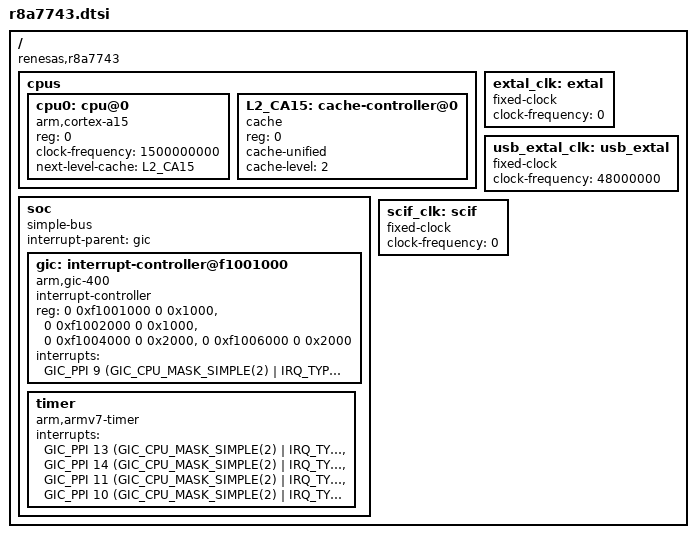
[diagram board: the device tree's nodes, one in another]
/*
 * Device Tree Source for the r8a7743 SoC
 *
 * Copyright (C) 2016 Cogent Embedded Inc.
 * Copyright (C) 2017 Renesas Electronics Corp.
 *
 * This file is licensed under the terms of the GNU General Public License
 * version 2. This program is licensed "as is" without any warranty of any
 * kind, whether express or implied.
 */

#include <dt-bindings/interrupt-controller/irq.h>
#include <dt-bindings/interrupt-controller/arm-gic.h>

/ {
	compatible = "renesas,r8a7743";
	#address-cells = <2>;
	#size-cells = <2>;

	cpus {
		#address-cells = <1>;
		#size-cells = <0>;

		cpu0: cpu@0 {
			device_type = "cpu";
			compatible = "arm,cortex-a15";
			reg = <0>;
			clock-frequency = <1500000000>;
			next-level-cache = <&L2_CA15>;
		};

		L2_CA15: cache-controller@0 {
			compatible = "cache";
			reg = <0>;
			cache-unified;
			cache-level = <2>;
		};
	};

	soc {
		compatible = "simple-bus";
		interrupt-parent = <&gic>;

		#address-cells = <2>;
		#size-cells = <2>;
		ranges;

		gic: interrupt-controller@f1001000 {
			compatible = "arm,gic-400";
			#interrupt-cells = <3>;
			#address-cells = <0>;
			interrupt-controller;
			reg = <0 0xf1001000 0 0x1000>,
			      <0 0xf1002000 0 0x1000>,
			      <0 0xf1004000 0 0x2000>,
			      <0 0xf1006000 0 0x2000>;
			interrupts = <GIC_PPI 9 (GIC_CPU_MASK_SIMPLE(2) |
						 IRQ_TYPE_LEVEL_HIGH)>;
		};

		timer {
			compatible = "arm,armv7-timer";
			interrupts = <GIC_PPI 13 (GIC_CPU_MASK_SIMPLE(2) |
						  IRQ_TYPE_LEVEL_LOW)>,
				     <GIC_PPI 14 (GIC_CPU_MASK_SIMPLE(2) |
						  IRQ_TYPE_LEVEL_LOW)>,
				     <GIC_PPI 11 (GIC_CPU_MASK_SIMPLE(2) |
						  IRQ_TYPE_LEVEL_LOW)>,
				     <GIC_PPI 10 (GIC_CPU_MASK_SIMPLE(2) |
						  IRQ_TYPE_LEVEL_LOW)>;
		};
	};

	/* External root clock */
	extal_clk: extal {
		compatible = "fixed-clock";
		#clock-cells = <0>;
		/* This value must be overridden by the board. */
		clock-frequency = <0>;
	};

	/* External USB clock - can be overridden by the board */
	usb_extal_clk: usb_extal {
		compatible = "fixed-clock";
		#clock-cells = <0>;
		clock-frequency = <48000000>;
	};

	/* External SCIF clock */
	scif_clk: scif {
		compatible = "fixed-clock";
		#clock-cells = <0>;
		/* This value must be overridden by the board. */
		clock-frequency = <0>;
	};
};
